# RA register map
Vendor: Renesas; Series: All Chips; File version: x.xx
Registers are 32-bit, read-write, reset 0x0 unless marked. A register's access mark holds for its fields unless they carry their own. Offsets are from the block's base; [hi:lo] are bit positions; {n}, {i} and the like mark numbered series.

## R_GPT_POEG0 — Port Output Enable for GPT
Base 0x40042000
Same registers: R_GPT_POEG1 0x40042100, R_GPT_POEG2 0x40042200, R_GPT_POEG3 0x40042300
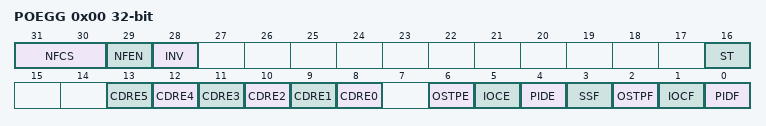
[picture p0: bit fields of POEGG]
0x00 POEGG — POEG Group Setting Register
  [31:30] NFCS — Noise Filter Clock Select
    0=Sampling GTETRG pin input level for three times in every PCLKB; 1=Sampling GTETRG pin input level for three times in every PCLKB /8; 2=Sampling GTETRG pin input level for three times in every PCLKB /32; 3=Sampling GTETRG pin input level for three times in every PCLKB /128
  [29] NFEN — Noise Filter Enable
    0=Filtering noise disabled; 1=Filtering noise enabled
  [28] INV — GTETRG Input Reverse
    0=GTETRG Input; 1=GTETRG Input Reversed
  [16] ST ro — GTETRG Input Status Flag
    0=GTETRG input after filtering is 0; 1=GTETRG input after filtering is 1
  [n+8] CDRE{n} (n=0..5) — Comparator Disable Request Enable. Note: Can be modified only once after a reset.
    0=A disable request of comparator 0 disabled; 1=A disable request of comparator 0 enabled
  [6] OSTPE — Oscillation Stop Detection EnableNote: Can be modified only once after a reset.
    0=A output-disable request from the oscillation stop detection disabled; 1=A output-disable request from the oscillation stop detection enabled
  [5] IOCE — Enable for GPT Output-Disable RequestNote: Can be modified only once after a reset.
    0=Disable output-disable requests from GPT disable request; 1=Enable output-disable requests from GPT disable request
  [4] PIDE — Port Input Detection EnableNote: Can be modified only once after a reset.
    0=A output-disable request from the GTETRG pins disabled; 1=A output-disable request from the GTETRG pins enabled
  [3] SSF — Software Stop Flag
    0=A output-disable request from software has not been generated; 1=A output-disable request from software has been generated
  [2] OSTPF write-0-clears read-modifies — Oscillation Stop Detection Flag
    0=A output-disable request from the oscillation stop detection has not been generated; 1=A output-disable request from the oscillation stop detection has been generated
  [1] IOCF write-0-clears read-modifies — Real Time Overcurrent Detection Flag
    0=A output-disable request from GPT disable request or comparator interrupt has not been generated; 1=A output-disable request from GPT disable request or comparator interrupt has been generated
  [0] PIDF write-0-clears read-modifies — Port Input Detection Flag
    0=A output-disable request from the GTETRG pin has not been generated; 1=A output-disable request from the GTETRG pin has been generated

## R_IRDA — IrDA Interface
Base 0x40070F00
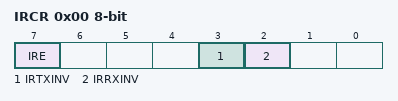
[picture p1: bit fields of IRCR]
0x00 IRCR 8-bit — IrDA Control Register
  [7] IRE — IrDA Enable
    0=Serial I/O pins are used for normal serial communication; 1=Serial I/O pins are used for IrDA data communication
  [3] IRTXINV — IRTXD Polarity Switching
    0=Data to be transmitted is output to IRTXD as is; 1=Data to be transmitted is output to IRTXD after the polarity is inverted
  [2] IRRXINV — IRRXD Polarity Switching
    0=IRRXD input is used as received data as is; 1=IRRXD input is used as received data after the polarity is inverted

## R_IWDT — Independent Watchdog Timer
Base 0x40044400
0x00 IWDTRR 8-bit reset 0xFF — IWDT Refresh Register
  [7:0] IWDTRR — The counter is refreshed by writing 0x00 and then writing 0xFF to this register.
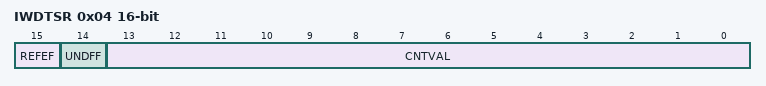
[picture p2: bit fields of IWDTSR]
0x04 IWDTSR 16-bit — IWDT Status Register
  [15] REFEF write-0-clears read-modifies — Refresh Error Flag
    0=Refresh error not occurred; 1=Refresh error occurred
  [14] UNDFF write-0-clears read-modifies — Underflow Flag
    0=Underflow not occurred; 1=Underflow occurred
  [13:0] CNTVAL ro — Counter ValueValue counted by the counter
